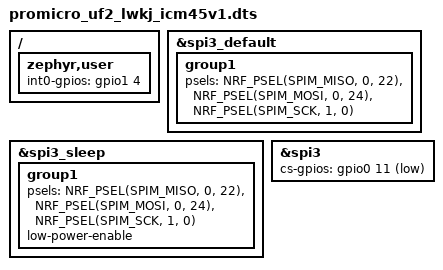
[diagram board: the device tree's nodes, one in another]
// Copyright (c) 2024 Nordic Semiconductor ASA
// SPDX-License-Identifier: Apache-2.0

/dts-v1/;
#include "promicro_uf2.dts"

/delete-node/ &i2c0;

&spi3_default {
	group1 {
		psels = <NRF_PSEL(SPIM_MISO, 0, 22)>,
				<NRF_PSEL(SPIM_MOSI, 0, 24)>,
				<NRF_PSEL(SPIM_SCK, 1, 0)>;
	};
};

&spi3_sleep {
	group1 {
		psels = <NRF_PSEL(SPIM_MISO, 0, 22)>,
				<NRF_PSEL(SPIM_MOSI, 0, 24)>,
				<NRF_PSEL(SPIM_SCK, 1, 0)>;
		low-power-enable;
	};
};

/ {
	zephyr,user {
		int0-gpios = <&gpio1 4 0>;
		/delete-property/ clk-gpios;
	};
};

&spi3 {
	cs-gpios = <&gpio0 11 GPIO_ACTIVE_LOW>;
};
